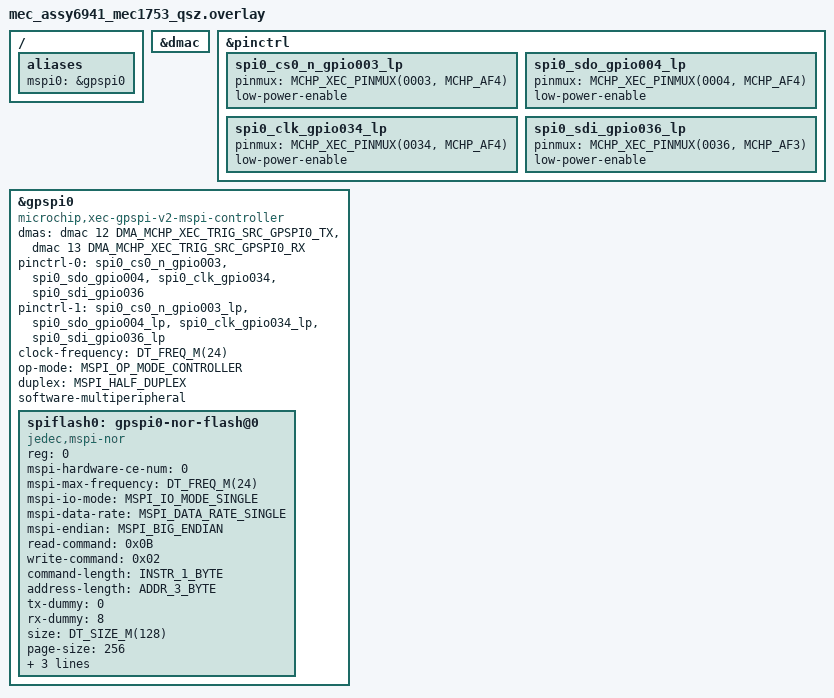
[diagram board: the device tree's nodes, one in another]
/*
 * Copyright (c) 2026 Nordic Semiconductor ASA
 * Copyright (c) 2026 Microchip Technology Inc.
 *
 * SPDX-License-Identifier: Apache-2.0
 */

#include <zephyr/dt-bindings/dma/mchp-xec-dmac.h>

/* mec_assy6941 EVB with MEC1753 daughter card.
 * Winbond 25Q128JVSM +3.3V installed in socket U6
 * Jumper block JP15 3x6
 * 2-3 ON
 * 5-6 ON
 * 8-9 ON
 * 11-12 ON
 * 17-18 ON
 * Jumper block JP85 3x4
 * 1-2 ON
 * 4-5 ON
 * 7-8 ON
 * 10-11 ON
 * Jumper block JP86 1x3
 * 2-3 ON
 */

/ {
	aliases {
		mspi0 = &gpspi0;
	};
};

&dmac {
	status = "okay";
};

&pinctrl {
	spi0_cs0_n_gpio003_lp: spi0_cs0_n_gpio003_lp {
		pinmux = <MCHP_XEC_PINMUX(0003, MCHP_AF4)>;
		low-power-enable;
	};

	spi0_sdo_gpio004_lp: spi0_sdo_gpio004_lp {
		pinmux = <MCHP_XEC_PINMUX(0004, MCHP_AF4)>;
		low-power-enable;
	};

	spi0_clk_gpio034_lp: spi0_clk_gpio034_lp {
		pinmux = <MCHP_XEC_PINMUX(0034, MCHP_AF4)>;
		low-power-enable;
	};

	spi0_sdi_gpio036_lp: spi0_sdi_gpio036_lp {
		pinmux = <MCHP_XEC_PINMUX(0036, MCHP_AF3)>;
		low-power-enable;
	};
};

&gpspi0 {
	compatible = "microchip,xec-gpspi-v2-mspi-controller";
	status = "okay";

	dmas = <&dmac 12 DMA_MCHP_XEC_TRIG_SRC_GPSPI0_TX>,
	       <&dmac 13 DMA_MCHP_XEC_TRIG_SRC_GPSPI0_RX>;
	dma-names = "tx", "rx";

	pinctrl-0 = <&spi0_cs0_n_gpio003 &spi0_sdo_gpio004
		     &spi0_clk_gpio034 &spi0_sdi_gpio036>;
	pinctrl-1 = <&spi0_cs0_n_gpio003_lp &spi0_sdo_gpio004_lp
		     &spi0_clk_gpio034_lp &spi0_sdi_gpio036_lp>;
	pinctrl-names = "default", "sleep";

	clock-frequency = <DT_FREQ_M(24)>; /* Maximum frequency we allow. HW limit is 48MHz*/
	op-mode = "MSPI_OP_MODE_CONTROLLER";
	duplex = "MSPI_HALF_DUPLEX";
	software-multiperipheral; /* REQUIRED */

	spiflash0: gpspi0-nor-flash@0 {
		compatible = "jedec,mspi-nor";
		reg = <0>;

		mspi-hardware-ce-num = <0>;
		mspi-max-frequency = <DT_FREQ_M(24)>;
		mspi-io-mode = "MSPI_IO_MODE_SINGLE";
		mspi-data-rate = "MSPI_DATA_RATE_SINGLE";
		mspi-endian = "MSPI_BIG_ENDIAN";
		read-command = <0x0B>;
		write-command = <0x02>;
		command-length = "INSTR_1_BYTE";
		address-length = "ADDR_3_BYTE";
		tx-dummy = <0>;
		rx-dummy = <8>;
		size = <DT_SIZE_M(128)>;
		page-size = <256>;
		quad-enable-requirements = "S2B1v4";
		jedec-id = [ef 70 18];
		sfdp-bfp = [00];
		status = "okay";
	};
};
